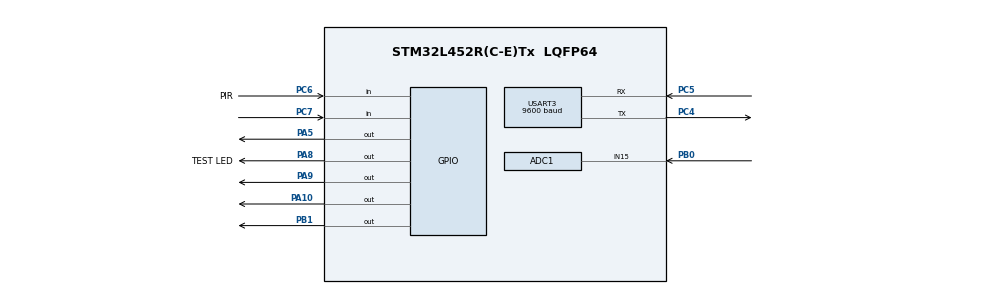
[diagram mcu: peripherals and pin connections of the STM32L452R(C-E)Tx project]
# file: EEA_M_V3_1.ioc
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ADC1.Channel-0\#ChannelRegularConversion=ADC_CHANNEL_15
ADC1.NbrOfConversionFlag=1
ADC1.OffsetNumber-0\#ChannelRegularConversion=ADC_OFFSET_NONE
ADC1.Rank-0\#ChannelRegularConversion=1
ADC1.SamplingTime-0\#ChannelRegularConversion=ADC_SAMPLETIME_2CYCLES_5
ADC1.master=1
Dma.Request0=USART3_RX
Dma.USART3_RX.0.Direction=DMA_PERIPH_TO_MEMORY
Dma.USART3_RX.0.Instance=DMA1_Channel3
Dma.USART3_RX.0.MemDataAlignment=DMA_MDATAALIGN_BYTE
Dma.USART3_RX.0.MemInc=DMA_MINC_ENABLE
Dma.USART3_RX.0.Mode=DMA_CIRCULAR
Dma.USART3_RX.0.PeriphDataAlignment=DMA_PDATAALIGN_BYTE
Dma.USART3_RX.0.PeriphInc=DMA_PINC_DISABLE
Dma.USART3_RX.0.Priority=DMA_PRIORITY_LOW
Mcu.Family=STM32L4
Mcu.Name=STM32L452R(C-E)Tx
Mcu.Package=LQFP64
NVIC.DMA1_Channel3_IRQn=true\:0\:0\:false\:false\:true\:false\:true\:true
NVIC.PriorityGroup=NVIC_PRIORITYGROUP_4
NVIC.USART3_IRQn=true\:0\:0\:false\:false\:true\:true\:true\:true
PA10.Signal=GPIO_Output
PA13\ (JTMS/SWDIO).Signal=SYS_JTMS-SWDIO
PA14\ (JTCK/SWCLK).Signal=SYS_JTCK-SWCLK
PA5.Signal=GPIO_Output
PA8.GPIO_Label=TEST LED
PA8.Signal=GPIO_Output
PA9.Signal=GPIO_Output
PB0.Signal=SharedAnalog_PB0
PB1.Signal=GPIO_Output
PB6.Signal=USART1_TX
PB7.Signal=USART1_RX
PC4.Mode=Asynchronous
PC4.Signal=USART3_TX
PC5.Mode=Asynchronous
PC5.Signal=USART3_RX
PC6.GPIO_Label=PIR
PC6.GPIO_PuPd=GPIO_PULLDOWN
PC6.Signal=GPIO_Input
PC7.GPIO_PuPd=GPIO_PULLUP
PC7.Signal=GPIO_Input
ProjectManager.HeapSize=0x200
ProjectManager.StackSize=0x400
ProjectManager.TargetToolchain=STM32CubeIDE
RCC.ADCFreq_Value=32000000
RCC.HSE_VALUE=8000000
RCC.HSI48_VALUE=48000000
RCC.HSI_VALUE=16000000
RCC.LSE_VALUE=32768
RCC.MSI_VALUE=4000000
RCC.PLLSAI1N=16
RCC.USBFreq_Value=32000000
RCC.VCOOutputFreq_Value=32000000
SH.SharedAnalog_PB0.0=GPIO_Analog
SH.SharedAnalog_PB0.1=ADC1_IN15,IN15-Single-Ended
USART3.BaudRate=9600
USART3.VirtualMode-Asynchronous=VM_ASYNC
board=custom

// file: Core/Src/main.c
/* USER CODE BEGIN Header */
/**
  ******************************************************************************
  * @file           : main.c
  * @brief          : Main program body
  * 전기조명설비 M main.c 파일
  * Author: PARK JANG HO
  ******************************************************************************
  * @attention
  *
  * Copyright (c) 2025 STMicroelectronics.
  * All rights reserved.
  *
  * This software is licensed under terms that can be found in the LICENSE file
  * in the root directory of this software component.
  * If no LICENSE file comes with this software, it is provided AS-IS.
  *
  ******************************************************************************
  */
/* USER CODE END Header */
#include "main.h"
#include "adc.h"
#include "dma.h"
#include "usart.h"
#include "gpio.h"

#include <E220-900T22D.h>
#include <E220_Config.h>
#include <NNFQueue.h>
#include <string.h>
#include <stdio.h>
#include <Sensor.h>
#include "../../Module/EEA_protocol/Inc/protocol.h"

/* USER CODE BEGIN PD */
#define SENSOR_UPDATE_INTERVAL_MS 2000 ///< 센서 상태를 주기적으로 검사할 간격
/*---------------------------[ 전역 변수 정의 ]---------------------------*/
uint32_t lastSensorProcessTime = 0;
uint8_t rx_byte = 0;

#define RX_BUFFER_SIZE 32
static element rxBuffer[RX_BUFFER_SIZE];
CircularQueue rxQueue;

/**< 마지막으로 송신한 EEA 패킷 */
volatile EEAPacket_t latestTxPacket;
/**< 마지막으로 수신한 EEA 패킷 */
volatile EEAPacket_t latestRxPacket;

/* USER CODE END PD */

void SystemClock_Config(void);

int main(void)
{

  /* MCU Configuration--------------------------------------------------------*/

  /* Reset of all peripherals, Initializes the Flash interface and the Systick. */
  HAL_Init();

  /* Configure the system clock */
  SystemClock_Config();

  /* Initialize all configured peripherals */
  MX_GPIO_Init();
  MX_DMA_Init();
  MX_ADC1_Init();
  MX_USART3_UART_Init();
  /* USER CODE BEGIN 2 */
  /* ------------------------[ 2. 통신 및 큐 초기화 ]------------------------ */
  bQueueinit(&rxQueue, rxBuffer, RX_BUFFER_SIZE);  ///< 수신용 순환 큐 초기화
  InitLoRaModule();                                 ///< LoRa 모듈 설정 및 통신 초기화
  HAL_Delay(500);                                   ///< LoRa 안정화 대기
  HAL_UART_Receive_IT(&huart3, (uint8_t*)&rx_byte, 1); ///< UART 수신 인터럽트 등록 (1바이트)

  /* ------------------------[ 3. 센서 초기화 ]------------------------ */
  InitAllSensors();                                 ///< PIR / CDS / LED 관련 초기 설정
  lastSensorProcessTime = HAL_GetTick();            ///< 센서 주기 처리 기준 시각 설정

  /* USER CODE END 2 */

  /* Infinite loop */
  /* USER CODE BEGIN WHILE */
  /* ------------------------[ 4. 메인 루프 ]------------------------ */
     while (1) {
         uint32_t now = HAL_GetTick();  ///< 현재 시각 갱신

         // (1) 센서 상태 주기적 검사
         if (now - lastSensorProcessTime >= SENSOR_UPDATE_INTERVAL_MS) {
             lastSensorProcessTime = now;
             ProcessAllSensors();       ///< PIR, CDS 상태 검사 및 LED 상태 보고
         }
             ProcessLoRaReception();    ///< LoRa 패킷 파싱 및 명령 처리
      }
}

void HAL_UART_RxCpltCallback(UART_HandleTypeDef *huart) {
   if (huart->Instance == USART3) {
      bEnqueue(&rxQueue, rx_byte);  ///< 수신 바이트를 큐에 삽입
      ///< 다음 바이트 수신 대기 (인터럽트 재등록)
      HAL_UART_Receive_IT(&huart3, &rx_byte, 1);
   }
}
void HAL_UART_ErrorCallback(UART_HandleTypeDef *huart) {
   if (huart == &huart3) {
      HAL_UART_Receive_IT(huart, (uint8_t*) &rx_byte, 1);
   }
}
void SystemClock_Config(void)
{
  RCC_OscInitTypeDef RCC_OscInitStruct = {0};
  RCC_ClkInitTypeDef RCC_ClkInitStruct = {0};

  /** Configure the main internal regulator output voltage
  */
  if (HAL_PWREx_ControlVoltageScaling(PWR_REGULATOR_VOLTAGE_SCALE1) != HAL_OK)
  {
    Error_Handler();
  }

  /** Initializes the RCC Oscillators according to the specified parameters
  * in the RCC_OscInitTypeDef structure.
  */
  RCC_OscInitStruct.OscillatorType = RCC_OSCILLATORTYPE_MSI;
  RCC_OscInitStruct.MSIState = RCC_MSI_ON;
  RCC_OscInitStruct.MSICalibrationValue = 0;
  RCC_OscInitStruct.MSIClockRange = RCC_MSIRANGE_6;
  RCC_OscInitStruct.PLL.PLLState = RCC_PLL_NONE;
  if (HAL_RCC_OscConfig(&RCC_OscInitStruct) != HAL_OK)
  {
    Error_Handler();
  }

  /** Initializes the CPU, AHB and APB buses clocks
  */
  RCC_ClkInitStruct.ClockType = RCC_CLOCKTYPE_HCLK|RCC_CLOCKTYPE_SYSCLK
                              |RCC_CLOCKTYPE_PCLK1|RCC_CLOCKTYPE_PCLK2;
  RCC_ClkInitStruct.SYSCLKSource = RCC_SYSCLKSOURCE_MSI;
  RCC_ClkInitStruct.AHBCLKDivider = RCC_SYSCLK_DIV1;
  RCC_ClkInitStruct.APB1CLKDivider = RCC_HCLK_DIV1;
  RCC_ClkInitStruct.APB2CLKDivider = RCC_HCLK_DIV1;

  if (HAL_RCC_ClockConfig(&RCC_ClkInitStruct, FLASH_LATENCY_0) != HAL_OK)
  {
    Error_Handler();
  }
}

void Error_Handler(void)
{
  __disable_irq();
  while (1)
  {
  }
}
